# PY32F001Cxx register map
Vendor: Puya; Series: PY32F0; File version: 1.0.0
Arm 32-bit Cortex-M0+ Microcontroller based device, CPU clock up to 48 MHz.
CPU: CM0+ r0p1, little endian, no MPU, no FPU, 4 interrupt priority bits
Registers are 32-bit, read-write, reset 0x0 unless marked. A register's access mark holds for its fields unless they carry their own. Offsets are from the block's base; lines under a group give offsets from that group; [hi:lo] are bit positions; {n}, {i} and the like mark numbered series; 'fields as' and 'values as' point back to an identical list; <NAME> marks a mode.

## Memory map
0x40002400 TIM14 size 0x60
0x40002800 PWM size 0x40
0x40003000 IWDG size 0x400 — Independent watchdog
0x40005400 I2C size 0x400 — Inter integrated circuit
0x40007000 PWR size 0x400 — Power control
0x40007C00 LPTIM1 size 0x400 — Low power timer
0x40010000 SYSCFG size 0x30 — System configuration controller
0x40010100 VREF size 0x10
0x40010200 COMP1 size 0x10 — Comparator 1
0x40010210 COMP2 size 0x10 — Comparator2
0x40010300 OPA size 0x40
0x40012400 ADC size 0x400 — Analog to Digital Converter
0x40012C00 TIM1 size 0x400 — Advanced timer
0x40013000 SPI1 size 0x400 — Serial peripheral interface
0x40013800 USART1 size 0x400 — Universal synchronous asynchronous receiver transmitter
0x40015800 DBGMCU size 0x400 — Debug support
0x40021000 RCC size 0x400 — Reset and clock control
0x40021800 EXTI size 0x400 — External interrupt/event controller
0x40022000 FLASH size 0x400
0x40023000 CRC size 0x400 — CRC calculation unit
0x50000000 GPIOA size 0x400 — General-purpose I/Os
0x50000400 GPIOB size 0x400
0x50000800 GPIOC size 0x400 — General-purpose I/Os
0x50000C00 GPIOD size 0x30

## Interrupts
3 FLASH — FLASH global Interrupt
4 RCC — RCC global Interrupt
5 EXTI0_1 (EXTI) — EXTI Line 0 and 1 Interrupt
6 EXTI2_3 (EXTI) — EXTI Line 2 and 3 Interrupt
7 EXTI4_15 (EXTI) — EXTI Line 4 to 15 Interrupt
12 ADC_COMP (ADC, COMP1, COMP2) — ADC and COMP Interrupts
13 TIM1_BRK_UP_TRG_COM (TIM1) — TIM1 Break, Update, Trigger and Commutation Interrupt
14 TIM1_CC (TIM1) — TIM1 Capture Compare Interrupt
17 LPTIM1_DAC (LPTIM1) — LPTIM1, DAC global Interrupts
23 I2C1 (I2C) — I2C1 global Interrupt
25 SPI1 — SPI1 global Interrupt
27 USART1 — USART1 global Interrupt

## ADC — Analog to Digital Converter
Base 0x40012400
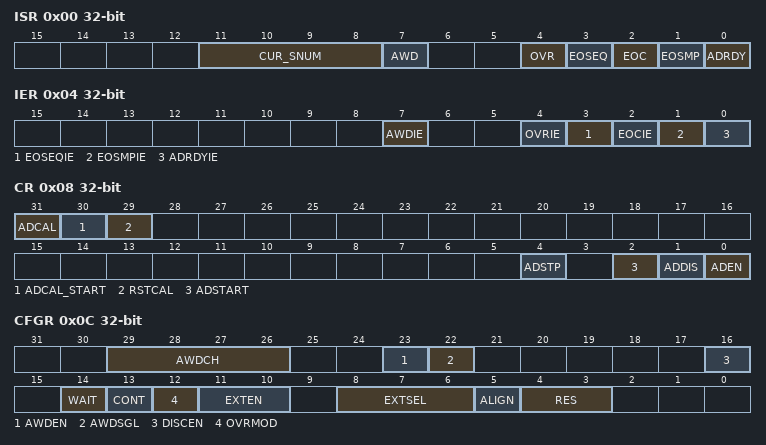
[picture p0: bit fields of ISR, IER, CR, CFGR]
0x00 ISR — ADC interrupt and status register
  [11:8] CUR_SNUM, [7] AWD, [4] OVR, [3] EOSEQ, [2] EOC, [1] EOSMP, [0] ADRDY
0x04 IER — ADC interrupt enable register
  [7] AWDIE, [4] OVRIE, [3] EOSEQIE, [2] EOCIE, [1] EOSMPIE, [0] ADRDYIE
0x08 CR — ADC control register
  [31] ADCAL, [30] ADCAL_START, [29] RSTCAL, [4] ADSTP, [2] ADSTART, [1] ADDIS, [0] ADEN
0x0C CFGR
  [29:26] AWDCH, [23] AWDEN, [22] AWDSGL, [16] DISCEN, [14] WAIT, [13] CONT, [12] OVRMOD, [11:10] EXTEN, [8:6] EXTSEL, [5] ALIGN, [4:3] RES
0x10 CFGR2 — ADC configuration register 2
  [31:28] CKMODE
0x14 SMPR — ADC sampling time register
  [2:0] SMP
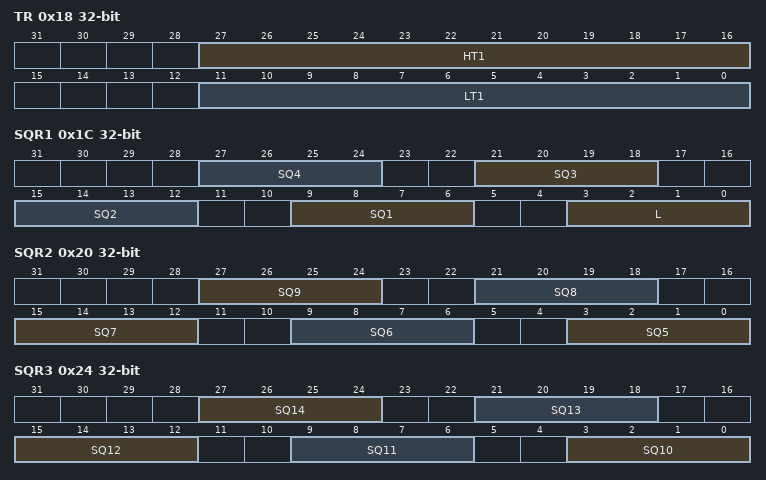
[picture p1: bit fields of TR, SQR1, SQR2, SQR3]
0x18 TR — ADC analog watchdog 1 threshold register
  [27:16] HT1, [11:0] LT1
0x1C SQR1
  [6n+3:6n] SQ{n} (n=1..4), [3:0] L
0x20 SQR2
  [6n-27:6n-30] SQ{n} (n=5..9)
0x24 SQR3
  [6n-57:6n-60] SQ{n} (n=10..14)
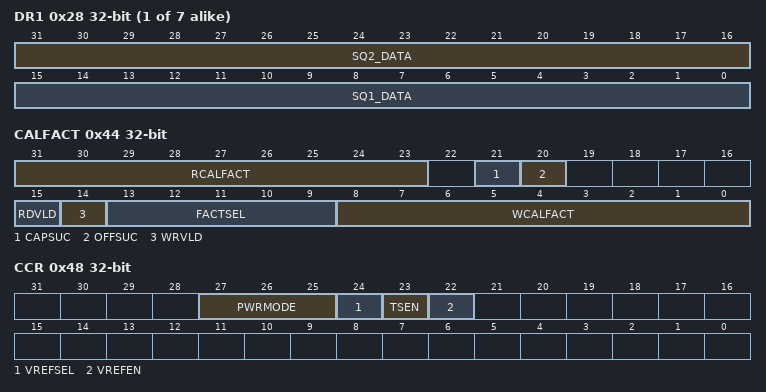
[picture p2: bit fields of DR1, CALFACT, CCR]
{0x24+4i} DR{i} (i=1..7)
  [31:16] SQ{2i}_DATA ro, [15:0] SQ{2i-1}_DATA ro
0x44 CALFACT
  [31:23] RCALFACT ro, [21] CAPSUC, [20] OFFSUC, [15] RDVLD, [14] WRVLD, [13:9] FACTSEL, [8:0] WCALFACT
0x48 CCR — ADC common configuration register
  [27:25] PWRMODE, [24] VREFSEL, [23] TSEN, [22] VREFEN

## COMP1 — Comparator 1
Base 0x40010200
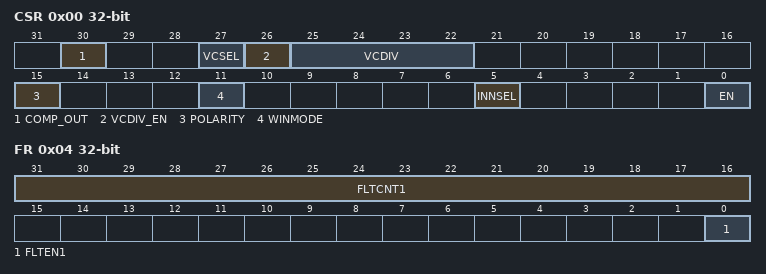
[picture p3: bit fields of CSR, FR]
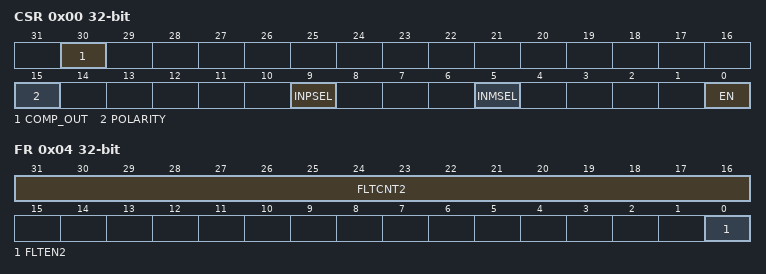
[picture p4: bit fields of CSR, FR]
0x00 CSR — COMP control and status register
  [30] COMP_OUT — Comparator output status
  [27] VCSEL
  [26] VCDIV_EN
  [25:22] VCDIV
  [15] POLARITY — Comparator polarity selector
  [11] WINMODE — Comparator non-inverting input selector for window mode
  [5] INNSEL
  [0] EN — COMP enable bit
0x04 FR — Comparator Filter register
  [31:16] FLTCNT1 — Comparator filter and counter
  [0] FLTEN1 — Filter enable bit

## COMP2 — Comparator2
Base 0x40010210
0x00 CSR — COMP control and status register
  [30] COMP_OUT — Comparator output status
  [15] POLARITY — Comparator polarity selector
  [9] INPSEL — Comparator signal selector for non-inverting input
  [5] INMSEL — Comparator signal selector for inverting input INM
  [0] EN — COMP enable bit
0x04 FR — Comparator Filter register
  [31:16] FLTCNT2 — Comparator filter and counter
  [0] FLTEN2 — Filter enable bit
